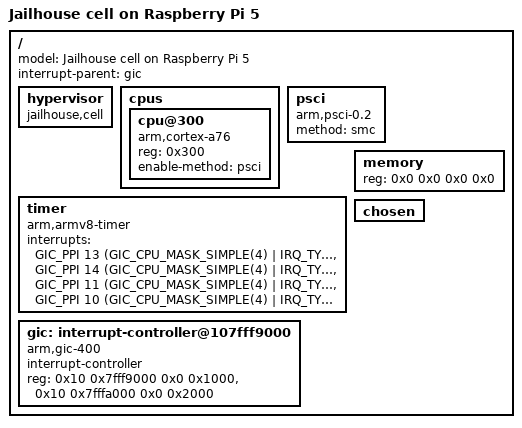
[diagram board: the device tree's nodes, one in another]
/*
 * Device tree for the PREEMPT_RT Linux guest on the Raspberry Pi 5
 * (cell config rpi5-linux-demo.c): CPU 3, GIC-400, arch timer, PSCI.
 * /memory and /chosen/bootargs are filled in by jailhouse-cell-linux.
 * Boot with: console=hvc0 earlycon=jailhouse
 *
 * This work is licensed under the terms of the GNU GPL, version 2.  See
 * the COPYING file in the top-level directory.
 */

#include <dt-bindings/interrupt-controller/arm-gic.h>

/dts-v1/;

/ {
	model = "Jailhouse cell on Raspberry Pi 5";

	#address-cells = <2>;
	#size-cells = <2>;

	interrupt-parent = <&gic>;

	hypervisor {
		compatible = "jailhouse,cell";
	};

	cpus {
		#address-cells = <1>;
		#size-cells = <0>;

		cpu@300 {
			compatible = "arm,cortex-a76";
			device_type = "cpu";
			reg = <0x300>;
			enable-method = "psci";
		};
	};

	psci {
		compatible = "arm,psci-0.2";
		method = "smc";
	};

	timer {
		compatible = "arm,armv8-timer";
		interrupts = <GIC_PPI 13 (GIC_CPU_MASK_SIMPLE(4) | IRQ_TYPE_LEVEL_LOW)>,
			     <GIC_PPI 14 (GIC_CPU_MASK_SIMPLE(4) | IRQ_TYPE_LEVEL_LOW)>,
			     <GIC_PPI 11 (GIC_CPU_MASK_SIMPLE(4) | IRQ_TYPE_LEVEL_LOW)>,
			     <GIC_PPI 10 (GIC_CPU_MASK_SIMPLE(4) | IRQ_TYPE_LEVEL_LOW)>;
	};

	gic: interrupt-controller@107fff9000 {
		compatible = "arm,gic-400";
		#interrupt-cells = <3>;
		interrupt-controller;
		reg = <0x10 0x7fff9000 0x0 0x1000>,
		      <0x10 0x7fffa000 0x0 0x2000>;
	};

	memory {
		device_type = "memory";
		reg = <0x0 0x0 0x0 0x0>;
	};

	chosen { };
};
